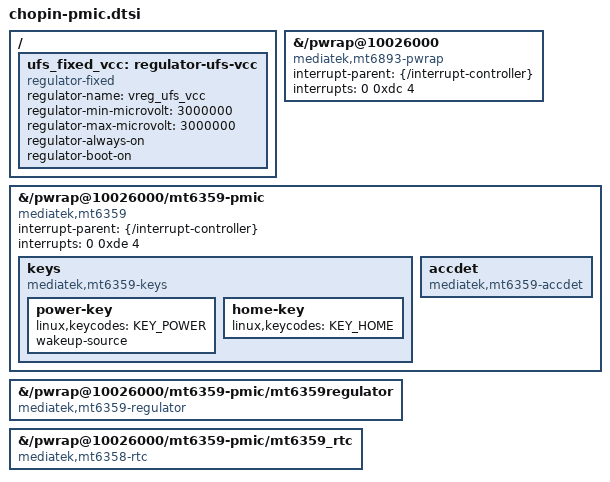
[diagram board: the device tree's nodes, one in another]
// SPDX-License-Identifier: GPL-2.0-only
/*
 * chopin: power wrapper and the MT6359 PMIC.
 */

&{/pwrap@10026000} {
	compatible = "mediatek,mt6893-pwrap", "syscon";
	interrupt-parent = <&{/interrupt-controller}>;
	interrupts = <0 0xdc 4>;
};

&{/pwrap@10026000/mt6359-pmic} {
	compatible = "mediatek,mt6359";
	interrupt-parent = <&{/interrupt-controller}>;
	interrupts = <0 0xde 4>;
};

/* vendor spells the regulator device "mt6359p-regulator" */
&{/pwrap@10026000/mt6359-pmic/mt6359regulator} {
	compatible = "mediatek,mt6359-regulator";
};

/*
 * The RTC node is "mediatek,mt6359-rtc" in the base tree, which nothing in
 * mainline knows: the MFD cell table in mt6397-core.c asks for
 * "mediatek,mt6358-rtc", and rtc-mt6397.c's match list has mt6358-rtc but no
 * mt6359-rtc.  Not matching causes
 *
 *   mt6359-rtc: Failed to locate of_node [id: -1]
 *
 * from mfd-core (the cell gets no of_node at all) and the RTC never registers.
 * Mainline files the MT6359 RTC under the mt6358 data, so say mt6358-rtc.
 */
&{/pwrap@10026000/mt6359-pmic/mt6359_rtc} {
	compatible = "mediatek,mt6358-rtc";
};

/*
 * Same class of problem as the RTC above, except here the base tree has no
 * child node at all, so mfd-core cannot find an of_node for the cell and warns
 * twice every boot:
 *
 *   mt6359-keys: Failed to locate of_node [id: -1]
 *   mt6359-accdet: Failed to locate of_node [id: -1]
 *
 * Add what mt6397-core.c's mt6359_devs[] asks for.  The keys driver
 * (mtk-pmic-keys.c) is built in now, and its child order maps to
 * irqnames[] = {"powerkey", "homekey"}, so the power key has to come first;
 * the PMIC's pwrkey IRQ is the phone's power button.  There is no mainline
 * mt6359-accdet driver, so that node only silences the warning - headset
 * detection still needs a driver.
 */
&{/pwrap@10026000/mt6359-pmic} {
	keys {
		compatible = "mediatek,mt6359-keys";

		power-key {
			linux,keycodes = <KEY_POWER>;
			wakeup-source;
		};

		home-key {
			linux,keycodes = <KEY_HOME>;
		};
	};

	accdet {
		compatible = "mediatek,mt6359-accdet";
	};
};

/*
 * The base tree wires UFS vcc to the MT6359's ldo_vemc, but that regulator is
 * never registered (the driver kept retrying with -EPROBE_DEFER):
 *
 *   ufshcd_get_vreg: vcc get failed, err=-517
 *
 * The boot chain has already powered and initialised the UFS for us
 * ("[UFS] info: ufs init OK", "VUFS12=1200000" in LK's own log), so the kernel
 * does not need to manage the rail.  Use an always-on fixed regulator, exactly
 * like the working board on this SoC does (ufs_dummy_vcc in
 * mt6893-infinix-x6710.dts).
 */
/ {
	ufs_fixed_vcc: regulator-ufs-vcc {
		compatible = "regulator-fixed";
		regulator-name = "vreg_ufs_vcc";
		regulator-min-microvolt = <3000000>;
		regulator-max-microvolt = <3000000>;
		regulator-always-on;
		regulator-boot-on;
	};
};

/* ---- Storage: UFS is what this device boots from ---- */
/*
 * The base tree's clock specifiers are VENDOR clock IDs and do not resolve
 * against our mainline clock providers - the driver reported
 *     ufshcd_init_clocks: ufs-clk clk get failed, -2
 * and the PHY could not find "unipro" at all.  Use the mainline names from
 * mt6893.dtsi instead.
 *
 * freq-table-hz must hold two entries (min/max) per clock; the base tree
 * carries eight values for its four vendor clocks, which the driver rejects
 * with "freq-table-hz len mismatch" -> clock parse failed -22.
 *
 * mediatek,ufs-disable-mcq is the one that finally matters: ufs-mediatek.c:713
 * turns it into UFS_MTK_CAP_DISABLE_MCQ, and :1286 then sets
 * UFSHCD_QUIRK_BROKEN_LSDBS_CAP, which stops ufshcd_hba_capabilities() from
 * trusting the controller's LSDB_SUPPORT bit.  Without it this legacy IP
 * (0x20160706) claims legacy single doorbell has been removed, hba->lsdb_sup
 * stays false, and the host dies with
 *     ufshcd_add_scsi_host: failed to initialize
 *         (legacy doorbell mode not supported)
 */
